# ATSAM4LS8A device description
Architecture: CORTEX-M4; Family: SAM4; Series: SAM4L
Registers are 32-bit, read-write, reset 0x0 unless marked. A register's access mark holds for its fields unless they carry their own. Offsets are from the block's base; [hi:lo] are bit positions; 'fields as' and 'values as' point back to an identical list.

## SMAP — System Manager Access Port
Instances: SMAP 0x400A3000
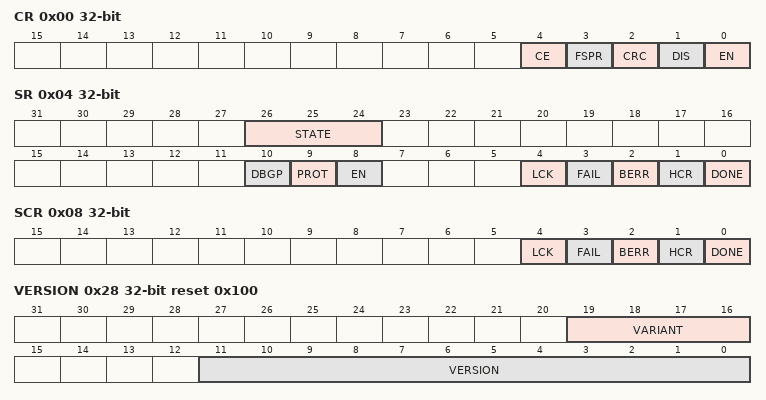
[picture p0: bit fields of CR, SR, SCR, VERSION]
0x00 CR wo — Control Register
  [4] CE — Chip Erase
  [3] FSPR — Flash Supplementary Page Read
  [2] CRC — User Page Read
  [1] DIS — Disable
  [0] EN — Enable
0x04 SR ro — Status Register
  [26:24] STATE
  [10] DBGP — Debugger Present
  [9] PROT — Protected
  [8] EN — Enabled
  [4] LCK — Lock
  [3] FAIL — Failure
  [2] BERR — Bus error
  [1] HCR — Hold Core reset
  [0] DONE — Operation done
0x08 SCR wo (atomic clear of SR) — Status Clear Register
  [4] LCK — Lock error
  [3] FAIL — Failure
  [2] BERR — Bus error
  [1] HCR — Hold Core Register
  [0] DONE
0x0C ADDR — Address Register
  [31:2] ADDR — Address Value
0x10 LENGTH
  [31:2] LENGTH
0x14 DATA
  [31:0] DATA — Generic data register
0x28 VERSION ro reset 0x100
  [19:16] VARIANT — Variant number
  [11:0] VERSION — Version number
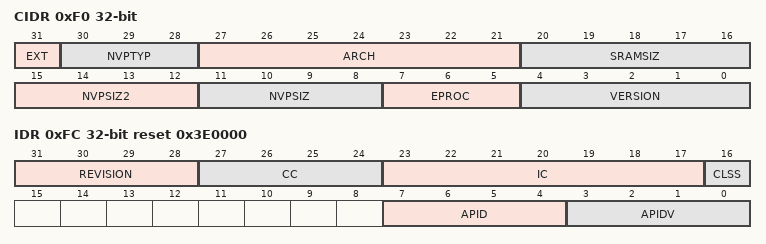
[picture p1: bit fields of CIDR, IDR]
0xF0 CIDR ro reset not defined — Chip ID Register
  [31] EXT — Extension Flag
  [30:28] NVPTYP — Nonvolatile Program Memory Type
  [27:21] ARCH — Architecture Identifier
  [20:16] SRAMSIZ — Internal SRAM Size
  [15:12] NVPSIZ2 — Second Nonvolatile Program Memory Size
  [11:8] NVPSIZ — Nonvolatile Program Memory Size
  [7:5] EPROC — Embedded Processor
  [4:0] VERSION — Version of the Device
0xF4 EXID ro reset not defined — Chip ID Extension Register
  [31:0] EXID — Chip ID Extension
0xFC IDR ro reset 0x3E0000 — AP Identification register
  [31:28] REVISION
  [27:24] CC — JEP-106 Continuation Code
  [23:17] IC — JEP-106 Identity Code
  [16] CLSS — Class
  [7:4] APID — AP Identification
  [3:0] APIDV — AP Identification Variant

## TRNG — True Random Number Generator
Instances: TRNG 0x40068000
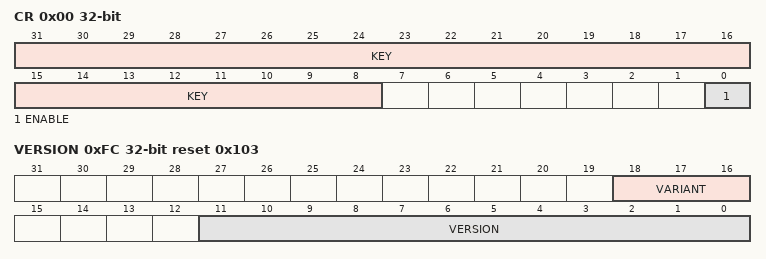
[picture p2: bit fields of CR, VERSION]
0x00 CR wo — Control Register
  [31:8] KEY — Security Key
  [0] ENABLE — Enables the TRNG to provide random values
0x10 IER wo (atomic set of IMR) — Interrupt Enable Register
  [0] DATRDY — Data Ready Interrupt Enable
0x14 IDR wo (atomic clear of IMR) — Interrupt Disable Register
  [0] DATRDY — Data Ready Interrupt Disable
0x18 IMR ro — Interrupt Mask Register
  [0] DATRDY — Data Ready Interrupt Mask
0x1C ISR ro — Interrupt Status Register
  [0] DATRDY — Data Ready Interrupt Status
0x50 ODATA ro — Output Data Register
  [0] ODATA — Output Data
0xFC VERSION ro reset 0x103
  [18:16] VARIANT — Variant Number
  [11:0] VERSION — Version Number

## TWIS — Two-wire Slave Interface
Instances: TWIS0 0x40018400, TWIS1 0x4001C400
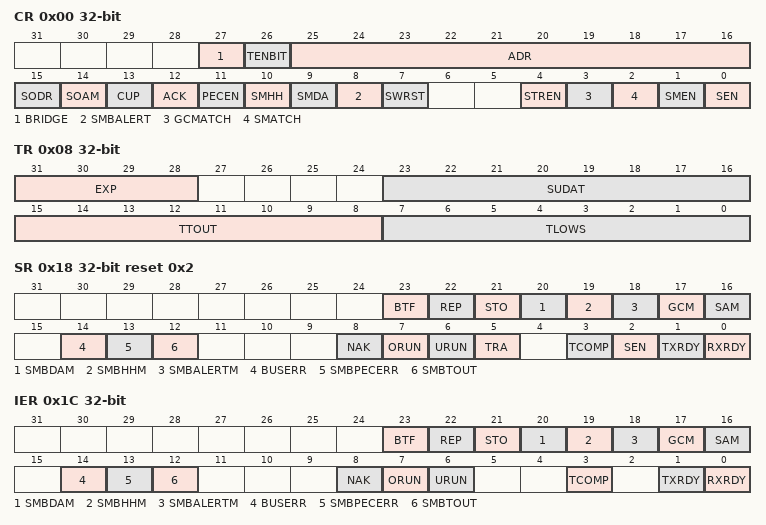
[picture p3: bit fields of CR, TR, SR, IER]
0x00 CR — Control Register
  [27] BRIDGE — Bridge Control Enable
  [26] TENBIT — Ten Bit Address Match
  [25:16] ADR — Slave Address
  [15] SODR — Stretch Clock on Data Byte Reception
  [14] SOAM — Stretch Clock on Address Match
  [13] CUP — NBYTES Count Up
  [12] ACK — Slave Receiver Data Phase ACK Value
  [11] PECEN — Packet Error Checking Enable
  [10] SMHH — SMBus Host Header
  [9] SMDA — SMBus Default Address
  [8] SMBALERT — SMBus Alert
  [7] SWRST — Software Reset
  [4] STREN — Clock Stretch Enable
  [3] GCMATCH — General Call Address Match
  [2] SMATCH — Slave Address Match
  [1] SMEN — SMBus Mode Enable
  [0] SEN — Slave Enable
0x04 NBYTES
  [7:0] NBYTES — Number of Bytes to Transfer
0x08 TR — Timing Register
  [31:28] EXP — Clock Prescaler
  [23:16] SUDAT — Data Setup Cycles
  [15:8] TTOUT — SMBus Ttimeout Cycles
  [7:0] TLOWS — SMBus Tlow:sext Cycles
0x0C RHR ro — Receive Holding Register
  [7:0] RXDATA — Received Data Byte
0x10 THR wo — Transmit Holding Register
  [7:0] TXDATA — Data Byte to Transmit
0x14 PECR ro — Packet Error Check Register
  [7:0] PEC — Calculated PEC Value
0x18 SR ro reset 0x2 — Status Register
  [23] BTF — Byte Transfer Finished
  [22] REP — Repeated Start Received
  [21] STO — Stop Received
  [20] SMBDAM — SMBus Default Address Match
  [19] SMBHHM — SMBus Host Header Address Match
  [18] SMBALERTM — SMBus Alert Response Address Match
  [17] GCM — General Call Match
  [16] SAM — Slave Address Match
  [14] BUSERR — Bus Error
  [13] SMBPECERR — SMBus PEC Error
  [12] SMBTOUT — SMBus Timeout
  [8] NAK — NAK Received
  [7] ORUN — Overrun
  [6] URUN — Underrun
  [5] TRA — Transmitter Mode
  [3] TCOMP — Transmission Complete
  [2] SEN — Slave Enabled
  [1] TXRDY — TX Buffer Ready
  [0] RXRDY — RX Buffer Ready
0x1C IER wo (atomic set of IMR) — Interrupt Enable Register
  [23] BTF — Byte Transfer Finished
  [22] REP — Repeated Start Received
  [21] STO — Stop Received
  [20] SMBDAM — SMBus Default Address Match
  [19] SMBHHM — SMBus Host Header Address Match
  [18] SMBALERTM — SMBus Alert Response Address Match
  [17] GCM — General Call Match
  [16] SAM — Slave Address Match
  [14] BUSERR — Bus Error
  [13] SMBPECERR — SMBus PEC Error
  [12] SMBTOUT — SMBus Timeout
  [8] NAK — NAK Received
  [7] ORUN — Overrun
  [6] URUN — Underrun
  [3] TCOMP — Transmission Complete
  [1] TXRDY — TX Buffer Ready
  [0] RXRDY — RX Buffer Ready
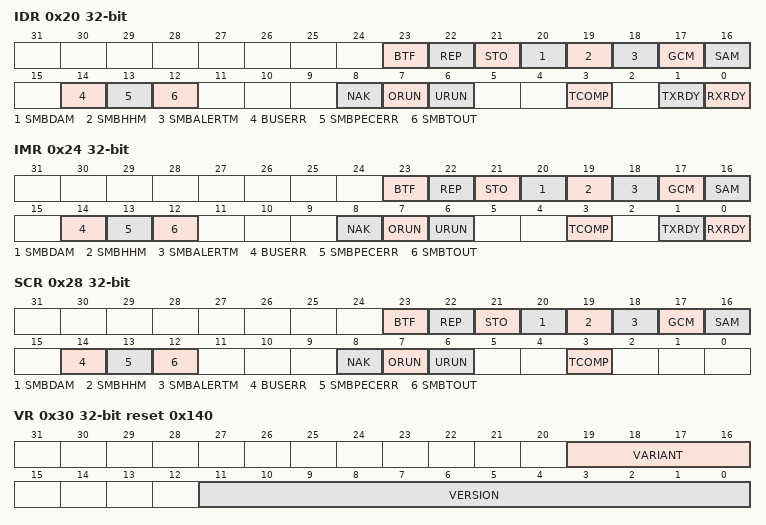
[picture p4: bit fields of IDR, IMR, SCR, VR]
0x20 IDR wo (atomic clear of IMR) — Interrupt Disable Register
  fields as IER
0x24 IMR ro — Interrupt Mask Register
  fields as IER
0x28 SCR wo (atomic clear of SR) — Status Clear Register
  [23] BTF — Byte Transfer Finished
  [22] REP — Repeated Start Received
  [21] STO — Stop Received
  [20] SMBDAM — SMBus Default Address Match
  [19] SMBHHM — SMBus Host Header Address Match
  [18] SMBALERTM — SMBus Alert Response Address Match
  [17] GCM — General Call Match
  [16] SAM — Slave Address Match
  [14] BUSERR — Bus Error
  [13] SMBPECERR — SMBus PEC Error
  [12] SMBTOUT — SMBus Timeout
  [8] NAK — NAK Received
  [7] ORUN — Overrun
  [6] URUN — Underrun
  [3] TCOMP — Transmission Complete
0x2C PR ro reset 0x1 — Parameter Register
  [0] HS — HS-mode
0x30 VR ro reset 0x140 — Version Register
  [19:16] VARIANT — Variant Number
  [11:0] VERSION — Version Number
0x34 HSTR — HS-mode Timing Register
  [23:16] HDDAT — Data Hold Cycles
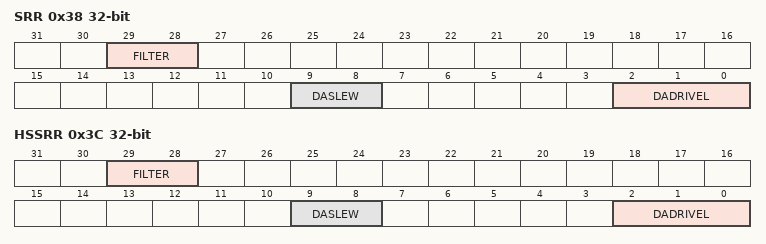
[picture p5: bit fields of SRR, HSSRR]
0x38 SRR — Slew Rate Register
  [29:28] FILTER — Input Spike Filter Control
  [9:8] DASLEW — Data Slew Limit
  [2:0] DADRIVEL — Data Drive Strength LOW
0x3C HSSRR — HS-mode Slew Rate Register
  fields as SRR
